# ipro7 register map
Vendor: intelpro; Series: BTBLE
CPU: ipro7, little endian
Registers are 32-bit, read-write, reset 0x0 unless marked. A register's access mark holds for its fields unless they carry their own. Offsets are from the block's base; [hi:lo] are bit positions; {n}, {i} and the like mark numbered series.

## USB
Base 0x30084000
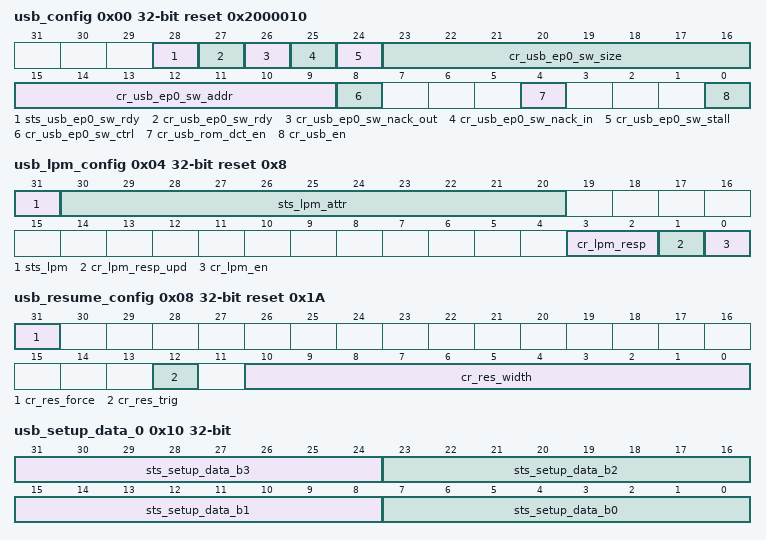
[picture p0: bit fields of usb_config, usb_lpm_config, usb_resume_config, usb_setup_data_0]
0x00 usb_config reset 0x2000010 (reset mask 0xEFFFFFFF)
  [28] sts_usb_ep0_sw_rdy ro — EP0 transaction ready status bit. Asserted with sw_rdy, and de-asserted when ACK is sent/received.
  [27] cr_usb_ep0_sw_rdy — EP0 transaction ready. When NACK is enabled, asserting this bit will allow one packet to be transferred even if NACK is asserted
  [26] cr_usb_ep0_sw_nack_out — EP0 OUT/SETUP transaction nack response (SW control mode) Note: Should NOT enable both ep0_sw_nack_out and ep0_sw_stall at the same time
  [25] cr_usb_ep0_sw_nack_in — EP0 IN transaction nack response (SW control mode) Note: Should NOT enable both ep0_sw_nack_in and ep0_sw_stall at the same time
  [24] cr_usb_ep0_sw_stall — EP0 stall response (SW control mode) Note: Should NOT enable both ep0_sw_nack_in/out and ep0_sw_stall at the same time
  [23:16] cr_usb_ep0_sw_size — EP0 transfer size (SW control mode)
  [15:9] cr_usb_ep0_sw_addr — EP0 address (SW control mode)
  [8] cr_usb_ep0_sw_ctrl — EP0 software control enable 1'b1: EP0 IN/OUT transaction is fully contolled by SW 1'b0: EP0 IN/OUT transaction is controlled by HW
  [4] cr_usb_rom_dct_en — Enable signal of ROM-based descriptors (don't care if ep0_sw_ctrl is asserted) 1'b1: USB descriptors stored in ROM will be used 1'b0: SW should prepare the descriptors requested by HOST
  [0] cr_usb_en — Enable signal of USB function
0x04 usb_lpm_config reset 0x8 (reset mask 0xFFFFF)
  [31] sts_lpm ro — LPM status bit
  [30:20] sts_lpm_attr ro — LPM attributes received in LPM packet
  [3:2] cr_lpm_resp — Response when LPM packet is received 2'd3: NYET 2'd2: STALL 2'd1: NACK 2'd0: ACK
  [1] cr_lpm_resp_upd — Response update signal (for async concern) Assert this bit when cr_lpm_resp is updated
  [0] cr_lpm_en — LPM enable signal
0x08 usb_resume_config reset 0x1A
  [31] cr_res_force — Force to output K-state
  [12] cr_res_trig — Resume K-state trigger
  [10:0] cr_res_width — Resume K-state width (unit: 2.67us)
0x10 usb_setup_data_0 reset not defined
  [31:24] sts_setup_data_b3 ro — Setup Data Byte3 (wValue[15:8])
  [23:16] sts_setup_data_b2 ro — Setup Data Byte2 (wValue[7:0])
  [15:8] sts_setup_data_b1 ro — Setup Data Byte1 (bRequest[7:0])
  [7:0] sts_setup_data_b0 ro — Setup Data Byte0 (bmRequestType[7:0])
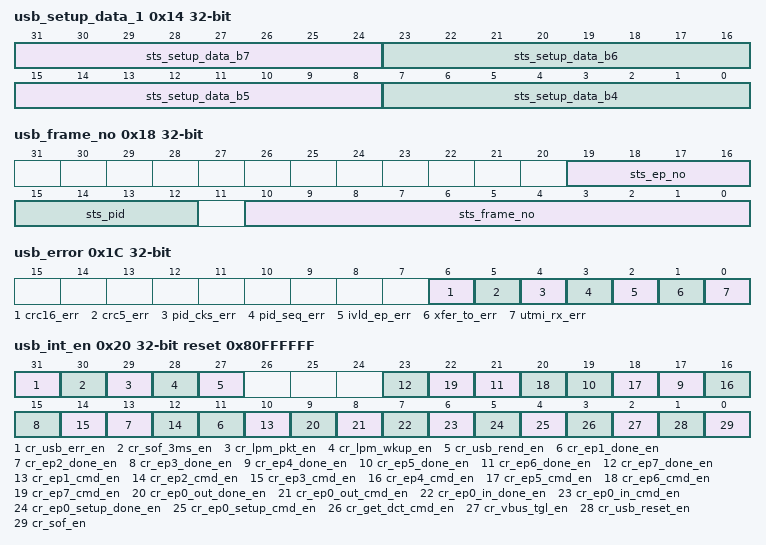
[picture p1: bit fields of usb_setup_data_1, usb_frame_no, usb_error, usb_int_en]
0x14 usb_setup_data_1 reset not defined
  [31:24] sts_setup_data_b7 ro — Setup Data Byte7 (wLength[15:8])
  [23:16] sts_setup_data_b6 ro — Setup Data Byte6 (wLength[7:0])
  [15:8] sts_setup_data_b5 ro — Setup Data Byte5 (wIndex[15:8])
  [7:0] sts_setup_data_b4 ro — Setup Data Byte4 (wIndex[7:0])
0x18 usb_frame_no (reset mask 0xFFF00800)
  [19:16] sts_ep_no ro — Endpoint number of the current transaction
  [15:12] sts_pid ro — PID value of the current transaction
  [10:0] sts_frame_no ro — Current frame number
0x1C usb_error (reset mask 0xFFFFFF80)
  [6] crc16_err ro — Data CRC error occurs, cleared by cr_usb_err_clr
  [5] crc5_err ro — Token CRC error occurs, cleared by cr_usb_err_clr
  [4] pid_cks_err ro — PID check sum error occurs, cleared by cr_usb_err_clr
  [3] pid_seq_err ro — PID sequence error occurs, cleared by cr_usb_err_clr
  [2] ivld_ep_err ro — Invalid endpoint error occurs, cleared by cr_usb_err_clr
  [1] xfer_to_err ro — Transfer time-out error occurs, cleared by cr_usb_err_clr
  [0] utmi_rx_err ro — UTMI I/F RX error occurs, cleared by cr_usb_err_clr
0x20 usb_int_en reset 0x80FFFFFF — USB interrupt enable
  [31] cr_usb_err_en — Interrupt enable of usb_err_int
  [30] cr_sof_3ms_en — Interrupt enable of sof_3ms_int
  [29] cr_lpm_pkt_en — Interrupt enable of lpm_pkt_int
  [28] cr_lpm_wkup_en — Interrupt enable of lpm_wkup_int
  [27] cr_usb_rend_en — Interrupt enable of usb_rend_int
  [2n+9] cr_ep{n}_done_en (n=1..7) — Interrupt enable of ep{n}_done_int
  [2n+8] cr_ep{n}_cmd_en (n=1..7) — Interrupt enable of ep{n}_cmd_int
  [9] cr_ep0_out_done_en — Interrupt enable of ep0_out_done_int
  [8] cr_ep0_out_cmd_en — Interrupt enable of ep0_out_cmd_int
  [7] cr_ep0_in_done_en — Interrupt enable of ep0_in_done_int
  [6] cr_ep0_in_cmd_en — Interrupt enable of ep0_in_cmd_int
  [5] cr_ep0_setup_done_en — Interrupt enable of ep0_setup_done_int
  [4] cr_ep0_setup_cmd_en — Interrupt enable of ep0_setup_cmd_int
  [3] cr_get_dct_cmd_en — Interrupt enable of get_dct_cmd_int
  [2] cr_vbus_tgl_en — Interrupt enable of vbus_tgl_int
  [1] cr_usb_reset_en — Interrupt enable of usb_reset_int
  [0] cr_sof_en — Interrupt enable of sof_int
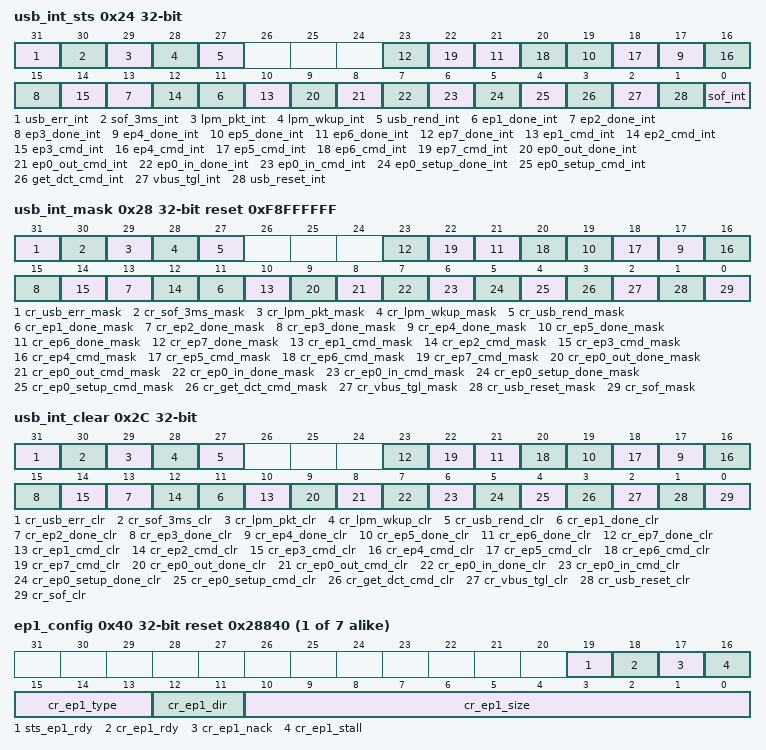
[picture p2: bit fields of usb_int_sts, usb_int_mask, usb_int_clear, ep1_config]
0x24 usb_int_sts (reset mask 0x7000000) — USB interrupt status
  [31] usb_err_int ro — USB error occurs, check usb_error for detailed error type
  [30] sof_3ms_int ro — SOF is absent for 3 ms
  [29] lpm_pkt_int ro — LPM packet is received
  [28] lpm_wkup_int ro — LPM resume (wakeup) signal is received
  [27] usb_rend_int ro — USB reset de-assert is triggered
  [2n+9] ep{n}_done_int ro (n=1..7) — EP{n} IN or OUT command is finished
  [2n+8] ep{n}_cmd_int ro (n=1..7) — EP{n} IN or OUT command is received
  [9] ep0_out_done_int ro — EP0 OUT command is finished
  [8] ep0_out_cmd_int ro — EP0 OUT command is received
  [7] ep0_in_done_int ro — EP0 IN command is finished
  [6] ep0_in_cmd_int ro — EP0 IN command is received
  [5] ep0_setup_done_int ro — EP0 SETUP command is finished
  [4] ep0_setup_cmd_int ro — EP0 SETUP command is received
  [3] get_dct_cmd_int ro — GET_DESCRIPTOR command is received
  [2] vbus_tgl_int ro — VBUS detection is toggled, check 0x1FC[31] for vbus_detect status
  [1] usb_reset_int ro — USB reset is triggered
  [0] sof_int ro — SOF is received
0x28 usb_int_mask reset 0xF8FFFFFF — USB interrupt mask
  [31] cr_usb_err_mask — Interrupt mask of usb_err_int
  [30] cr_sof_3ms_mask — Interrupt mask of sof_3ms_int
  [29] cr_lpm_pkt_mask — Interrupt mask of lpm_pkt_int
  [28] cr_lpm_wkup_mask — Interrupt mask of lpm_wkup_int
  [27] cr_usb_rend_mask — Interrupt mask of usb_rend_int
  [2n+9] cr_ep{n}_done_mask (n=1..7) — Interrupt mask of ep{n}_done_int
  [2n+8] cr_ep{n}_cmd_mask (n=1..7) — Interrupt mask of ep{n}_cmd_int
  [9] cr_ep0_out_done_mask — Interrupt mask of ep0_out_done_int
  [8] cr_ep0_out_cmd_mask — Interrupt mask of ep0_out_cmd_int
  [7] cr_ep0_in_done_mask — Interrupt mask of ep0_in_done_int
  [6] cr_ep0_in_cmd_mask — Interrupt mask of ep0_in_cmd_int
  [5] cr_ep0_setup_done_mask — Interrupt mask of ep0_setup_done_int
  [4] cr_ep0_setup_cmd_mask — Interrupt mask of ep0_setup_cmd_int
  [3] cr_get_dct_cmd_mask — Interrupt mask of get_dct_cmd_int
  [2] cr_vbus_tgl_mask — Interrupt mask of vbus_tgl_int
  [1] cr_usb_reset_mask — Interrupt mask of usb_reset_int
  [0] cr_sof_mask — Interrupt mask of sof_int
0x2C usb_int_clear — USB interrupt clear
  [31] cr_usb_err_clr — Interrupt clear of usb_err_int
  [30] cr_sof_3ms_clr — Interrupt clear of sof_3ms_int
  [29] cr_lpm_pkt_clr — Interrupt clear of lpm_pkt_int
  [28] cr_lpm_wkup_clr — Interrupt clear of lpm_wkup_int
  [27] cr_usb_rend_clr — Interrupt clear of usb_rend_int
  [2n+9] cr_ep{n}_done_clr (n=1..7) — Interrupt clear of ep{n}_done_int
  [2n+8] cr_ep{n}_cmd_clr (n=1..7) — Interrupt clear of ep{n}_cmd_int
  [9] cr_ep0_out_done_clr — Interrupt clear of ep0_out_done_int
  [8] cr_ep0_out_cmd_clr — Interrupt clear of ep0_out_cmd_int
  [7] cr_ep0_in_done_clr — Interrupt clear of ep0_in_done_int
  [6] cr_ep0_in_cmd_clr — Interrupt clear of ep0_in_cmd_int
  [5] cr_ep0_setup_done_clr — Interrupt clear of ep0_setup_done_int
  [4] cr_ep0_setup_cmd_clr — Interrupt clear of ep0_setup_cmd_int
  [3] cr_get_dct_cmd_clr — Interrupt clear of get_dct_cmd_int
  [2] cr_vbus_tgl_clr — Interrupt clear of vbus_tgl_int
  [1] cr_usb_reset_clr — Interrupt clear of usb_reset_int
  [0] cr_sof_clr — Interrupt clear of sof_int
{0x3C+4i} ep{i}_config reset 0x28840 (reset mask 0xFFF7FFFF) (i=1..7)
  [19] sts_ep{i}_rdy ro — Endpoint ready status bit. Asserted with ep_rdy, and de-asserted when ACK is sent/received.
  [18] cr_ep{i}_rdy — Endpoint ready. When Endpoint NACK is enabled, asserting this bit will allow one packet to be transferred
  [17] cr_ep{i}_nack — Endpoint NACK response enable, should not be enabled with STALL at the same time
  [16] cr_ep{i}_stall — Endpoint STALL response enable, should not be enabled with NACK at the same time
  [15:13] cr_ep{i}_type — Endpoint type 3'b101: CTRL 3'b010: ISO 3'b100: BULK 3'b000: INT Others: Reserved
  [12:11] cr_ep{i}_dir — Endpoint direction 2'b00: Disabled 2'b01: IN 2'b10: OUT 2'b11: Reserved
  [10:0] cr_ep{i}_size — Endpoint max packet size
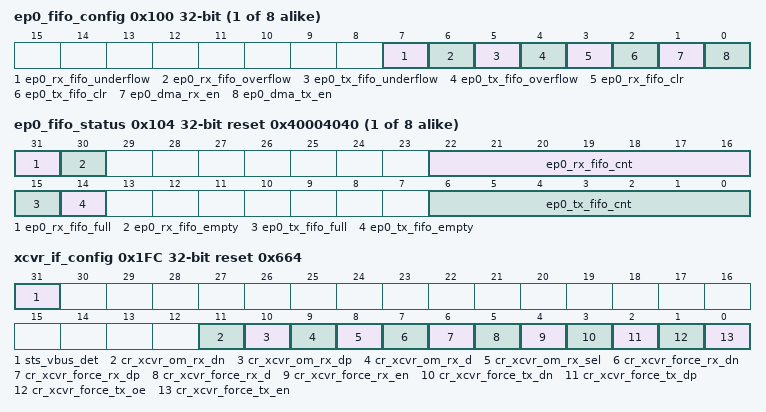
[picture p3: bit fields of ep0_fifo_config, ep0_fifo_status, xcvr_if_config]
{0x100+0x10*i} ep{i}_fifo_config (reset mask 0xFFFFFF0F) (i=0..7)
  [7] ep{i}_rx_fifo_underflow ro — Underflow flag of RX FIFO, can be cleared by rx_fifo_clr
  [6] ep{i}_rx_fifo_overflow ro — Overflow flag of RX FIFO, can be cleared by rx_fifo_clr
  [5] ep{i}_tx_fifo_underflow ro — Underflow flag of TX FIFO, can be cleared by tx_fifo_clr
  [4] ep{i}_tx_fifo_overflow ro — Overflow flag of TX FIFO, can be cleared by tx_fifo_clr
  [3] ep{i}_rx_fifo_clr — Clear signal of RX FIFO
  [2] ep{i}_tx_fifo_clr — Clear signal of TX FIFO
  [1] ep{i}_dma_rx_en — Enable signal of dma_rx_req/ack interface
  [0] ep{i}_dma_tx_en — Enable signal of dma_tx_req/ack interface
{0x104+0x10*i} ep{i}_fifo_status reset 0x40004040 (reset mask 0x3F803F80) (i=0..7)
  [31] ep{i}_rx_fifo_full ro — RX FIFO full flag
  [30] ep{i}_rx_fifo_empty ro — RX FIFO empty flag
  [22:16] ep{i}_rx_fifo_cnt ro — RX FIFO available count
  [15] ep{i}_tx_fifo_full ro — TX FIFO full flag
  [14] ep{i}_tx_fifo_empty ro — TX FIFO empty flag
  [6:0] ep{i}_tx_fifo_cnt ro — TX FIFO available count
{0x108+0x10*i} ep{i}_tx_fifo_wdata (i=0..7)
  [7:0] ep{i}_tx_fifo_wdata wo
{0x10C+0x10*i} ep{i}_rx_fifo_rdata (reset mask 0xFFFFFF00) (i=0..7)
  [7:0] ep{i}_rx_fifo_rdata ro
0x1F0 rsvd_0
0x1F4 rsvd_1
0x1FC xcvr_if_config reset 0x664 (reset mask 0x7FFFFFFF)
  [31] sts_vbus_det ro — Transceiver VBUS detection status
  [11] cr_xcvr_om_rx_dn — Transceiver RX signals output mode CR value
  [10] cr_xcvr_om_rx_dp — Transceiver RX signals output mode CR value
  [9] cr_xcvr_om_rx_d — Transceiver RX signals output mode CR value
  [8] cr_xcvr_om_rx_sel — Select signal of transceiver RX signals in output mode (tx_oe# = 0) 1'b0: rx_d/dp/dn is directly from transceiver 1'b1: rx_d/dp/dn is controlled by CR (cr_xcvr_om_rx_d/dp/dn)
  [7] cr_xcvr_force_rx_dn — Transceiver RX signals force mode value
  [6] cr_xcvr_force_rx_dp — Transceiver RX signals force mode value
  [5] cr_xcvr_force_rx_d — Transceiver RX signals force mode value
  [4] cr_xcvr_force_rx_en — Enable signal of transceiver RX signals force mode 1'b0: rx_d/dp/dn is from Transceiver 1'b1: tx_d/dp/dn is controlled by CR (cr_xcvr_force_rx_d/dp/dn)
  [3] cr_xcvr_force_tx_dn — Transceiver TX signals force mode value
  [2] cr_xcvr_force_tx_dp — Transceiver TX signals force mode value
  [1] cr_xcvr_force_tx_oe — Transceiver TX signals force mode value
  [0] cr_xcvr_force_tx_en — Enable signal of transceiver TX signals force mode 1'b0: tx_oe/dp/dn is controlled by HW 1'b1: tx_oe/dp/dn is controlled by CR (cr_xcvr_force_tx_oe/dp/dn)
